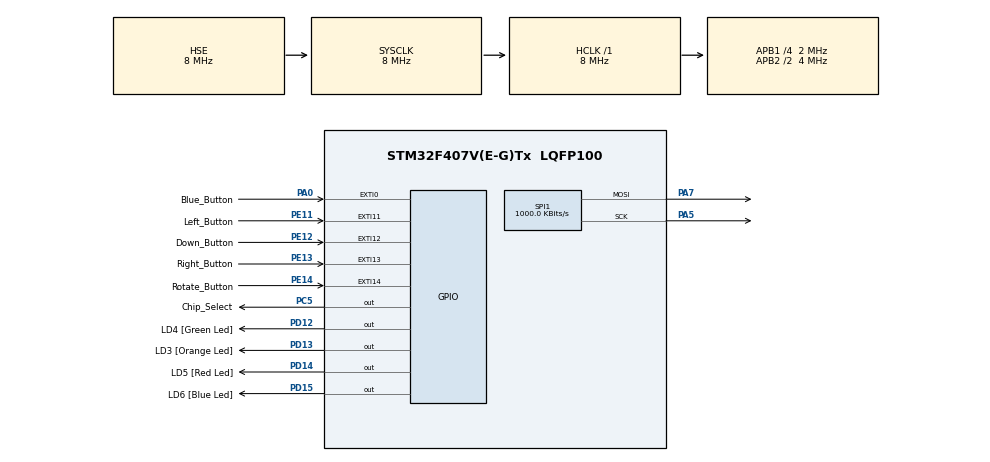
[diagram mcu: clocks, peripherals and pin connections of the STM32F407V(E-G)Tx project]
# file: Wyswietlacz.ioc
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Mcu.Family=STM32F4
Mcu.Name=STM32F407V(E-G)Tx
Mcu.Package=LQFP100
NVIC.EXTI0_IRQn=true\:0\:0\:false\:false\:true\:true
NVIC.EXTI15_10_IRQn=true\:0\:0\:false\:false\:true\:true
NVIC.PriorityGroup=NVIC_PRIORITYGROUP_0
NVIC.TIM1_UP_TIM10_IRQn=true\:0\:0\:false\:false\:true\:true
PA0-WKUP.GPIO_Label=Blue_Button
PA0-WKUP.Signal=GPXTI0
PA5.Mode=TX_Only_Simplex_Unidirect_Master
PA5.Signal=SPI1_SCK
PA7.Mode=TX_Only_Simplex_Unidirect_Master
PA7.Signal=SPI1_MOSI
PC5.GPIO_Label=Chip_Select
PC5.Signal=GPIO_Output
PD12.GPIO_Label=LD4 [Green Led]
PD12.GPIO_PuPd=GPIO_NOPULL
PD12.GPIO_Speed=GPIO_SPEED_FREQ_LOW
PD12.Signal=GPIO_Output
PD13.GPIO_Label=LD3 [Orange Led]
PD13.GPIO_PuPd=GPIO_NOPULL
PD13.GPIO_Speed=GPIO_SPEED_FREQ_LOW
PD13.Signal=GPIO_Output
PD14.GPIO_Label=LD5 [Red Led]
PD14.GPIO_PuPd=GPIO_NOPULL
PD14.GPIO_Speed=GPIO_SPEED_FREQ_LOW
PD14.Signal=GPIO_Output
PD15.GPIO_Label=LD6 [Blue Led]
PD15.GPIO_PuPd=GPIO_NOPULL
PD15.GPIO_Speed=GPIO_SPEED_FREQ_LOW
PD15.Signal=GPIO_Output
PE11.GPIO_Label=Left_Button
PE11.GPIO_ModeDefaultEXTI=GPIO_MODE_IT_FALLING
PE11.GPIO_PuPd=GPIO_PULLUP
PE11.Signal=GPXTI11
PE12.GPIO_Label=Down_Button
PE12.GPIO_ModeDefaultEXTI=GPIO_MODE_IT_FALLING
PE12.GPIO_PuPd=GPIO_PULLUP
PE12.Signal=GPXTI12
PE13.GPIO_Label=Right_Button
PE13.GPIO_ModeDefaultEXTI=GPIO_MODE_IT_FALLING
PE13.GPIO_PuPd=GPIO_PULLUP
PE13.Signal=GPXTI13
PE14.GPIO_Label=Rotate_Button
PE14.GPIO_ModeDefaultEXTI=GPIO_MODE_IT_FALLING
PE14.GPIO_PuPd=GPIO_PULLUP
PE14.Signal=GPXTI14
PH0-OSC_IN.Mode=HSE-External-Oscillator
PH0-OSC_IN.Signal=RCC_OSC_IN
PH1-OSC_OUT.Mode=HSE-External-Oscillator
PH1-OSC_OUT.Signal=RCC_OSC_OUT
ProjectManager.HeapSize=0x200
ProjectManager.StackSize=0x400
ProjectManager.TargetToolchain=SW4STM32
RCC.48MHZClocksFreq_Value=28571428.57142857
RCC.AHBFreq_Value=8000000
RCC.APB1CLKDivider=RCC_HCLK_DIV4
RCC.APB1Freq_Value=2000000
RCC.APB1TimFreq_Value=4000000
RCC.APB2CLKDivider=RCC_HCLK_DIV2
RCC.APB2Freq_Value=4000000
RCC.APB2TimFreq_Value=8000000
RCC.CortexFreq_Value=8000000
RCC.HCLKFreq_Value=8000000
RCC.HSE_VALUE=8000000
RCC.HSI_VALUE=16000000
RCC.LSE_VALUE=32768
RCC.PLLM=8
RCC.PLLN=100
RCC.PLLQ=7
RCC.SYSCLKFreq_VALUE=8000000
RCC.SYSCLKSource=RCC_SYSCLKSOURCE_HSE
RCC.VCOOutputFreq_Value=200000000
SPI1.BaudRatePrescaler=SPI_BAUDRATEPRESCALER_4
SPI1.CalculateBaudRate=1000.0 KBits/s
SPI1.DataSize=SPI_DATASIZE_16BIT
SPI1.Direction=SPI_DIRECTION_2LINES
SPI1.Mode=SPI_MODE_MASTER
SPI1.VirtualType=VM_MASTER
TIM10.Period=999
TIM10.Prescaler=8399
VP_RNG_VS_RNG.Mode=RNG_Activate
VP_TIM10_VS_ClockSourceINT.Mode=Enable_Timer
board=STM32F4DISCOVERY

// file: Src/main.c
/**
  ******************************************************************************
  * @file           : main.c
  * @brief          : Main program body
  ******************************************************************************
  ** This notice applies to any and all portions of this file
  * that are not between comment pairs USER CODE BEGIN and
  * USER CODE END. Other portions of this file, whether
  * inserted by the user or by software development tools
  * are owned by their respective copyright owners.
  *
  * COPYRIGHT(c) 2018 STMicroelectronics
  *
  * Redistribution and use in source and binary forms, with or without modification,
  * are permitted provided that the following conditions are met:
  *   1. Redistributions of source code must retain the above copyright notice,
  *      this list of conditions and the following disclaimer.
  *   2. Redistributions in binary form must reproduce the above copyright notice,
  *      this list of conditions and the following disclaimer in the documentation
  *      and/or other materials provided with the distribution.
  *   3. Neither the name of STMicroelectronics nor the names of its contributors
  *      may be used to endorse or promote products derived from this software
  *      without specific prior written permission.
  *
  * THIS SOFTWARE IS PROVIDED BY THE COPYRIGHT HOLDERS AND CONTRIBUTORS "AS IS"
  * AND ANY EXPRESS OR IMPLIED WARRANTIES, INCLUDING, BUT NOT LIMITED TO, THE
  * IMPLIED WARRANTIES OF MERCHANTABILITY AND FITNESS FOR A PARTICULAR PURPOSE ARE
  * DISCLAIMED. IN NO EVENT SHALL THE COPYRIGHT HOLDER OR CONTRIBUTORS BE LIABLE
  * FOR ANY DIRECT, INDIRECT, INCIDENTAL, SPECIAL, EXEMPLARY, OR CONSEQUENTIAL
  * DAMAGES (INCLUDING, BUT NOT LIMITED TO, PROCUREMENT OF SUBSTITUTE GOODS OR
  * SERVICES; LOSS OF USE, DATA, OR PROFITS; OR BUSINESS INTERRUPTION) HOWEVER
  * CAUSED AND ON ANY THEORY OF LIABILITY, WHETHER IN CONTRACT, STRICT LIABILITY,
  * OR TORT (INCLUDING NEGLIGENCE OR OTHERWISE) ARISING IN ANY WAY OUT OF THE USE
  * OF THIS SOFTWARE, EVEN IF ADVISED OF THE POSSIBILITY OF SUCH DAMAGE.
  *
  ******************************************************************************
  */
#include "main.h"
#include "stm32f4xx_hal.h"

/* USER CODE BEGIN Includes */
extern void GameLoop();
/* USER CODE END Includes */

RNG_HandleTypeDef hrng;

SPI_HandleTypeDef hspi1;

TIM_HandleTypeDef htim10;

/* USER CODE BEGIN PV */
/* Private variables ---------------------------------------------------------*/
/* USER CODE END PV */

void SystemClock_Config(void);
static void MX_GPIO_Init(void);
static void MX_SPI1_Init(void);
static void MX_RNG_Init(void);
static void MX_TIM10_Init(void);

/* USER CODE BEGIN PFP */
/* Private function prototypes -----------------------------------------------*/

/* USER CODE END PFP */

int main(void)
{

  /* MCU Configuration----------------------------------------------------------*/

  /* Reset of all peripherals, Initializes the Flash interface and the Systick. */
  HAL_Init();

  /* Configure the system clock */
  SystemClock_Config();

  /* Initialize all configured peripherals */
  MX_GPIO_Init();
  MX_SPI1_Init();
  MX_RNG_Init();
  MX_TIM10_Init();
  /* USER CODE BEGIN 2 */
  HAL_TIM_Base_Start_IT(&htim10);
  //RUN GAME !
  GameLoop();
  /* USER CODE END 2 */

  /* Infinite loop */
  while (1)
  {

  }

}

void SystemClock_Config(void)
{

  RCC_OscInitTypeDef RCC_OscInitStruct;
  RCC_ClkInitTypeDef RCC_ClkInitStruct;

    /**Configure the main internal regulator output voltage
    */
  __HAL_RCC_PWR_CLK_ENABLE();

  __HAL_PWR_VOLTAGESCALING_CONFIG(PWR_REGULATOR_VOLTAGE_SCALE1);

    /**Initializes the CPU, AHB and APB busses clocks
    */
  RCC_OscInitStruct.OscillatorType = RCC_OSCILLATORTYPE_HSI|RCC_OSCILLATORTYPE_HSE;
  RCC_OscInitStruct.HSEState = RCC_HSE_ON;
  RCC_OscInitStruct.HSIState = RCC_HSI_ON;
  RCC_OscInitStruct.HSICalibrationValue = 16;
  RCC_OscInitStruct.PLL.PLLState = RCC_PLL_ON;
  RCC_OscInitStruct.PLL.PLLSource = RCC_PLLSOURCE_HSI;
  RCC_OscInitStruct.PLL.PLLM = 8;
  RCC_OscInitStruct.PLL.PLLN = 100;
  RCC_OscInitStruct.PLL.PLLP = RCC_PLLP_DIV2;
  RCC_OscInitStruct.PLL.PLLQ = 7;
  if (HAL_RCC_OscConfig(&RCC_OscInitStruct) != HAL_OK)
  {
    _Error_Handler(__FILE__, __LINE__);
  }

    /**Initializes the CPU, AHB and APB busses clocks
    */
  RCC_ClkInitStruct.ClockType = RCC_CLOCKTYPE_HCLK|RCC_CLOCKTYPE_SYSCLK
                              |RCC_CLOCKTYPE_PCLK1|RCC_CLOCKTYPE_PCLK2;
  RCC_ClkInitStruct.SYSCLKSource = RCC_SYSCLKSOURCE_HSE;
  RCC_ClkInitStruct.AHBCLKDivider = RCC_SYSCLK_DIV1;
  RCC_ClkInitStruct.APB1CLKDivider = RCC_HCLK_DIV4;
  RCC_ClkInitStruct.APB2CLKDivider = RCC_HCLK_DIV2;

  if (HAL_RCC_ClockConfig(&RCC_ClkInitStruct, FLASH_LATENCY_0) != HAL_OK)
  {
    _Error_Handler(__FILE__, __LINE__);
  }

    /**Configure the Systick interrupt time
    */
  HAL_SYSTICK_Config(HAL_RCC_GetHCLKFreq()/1000);

    /**Configure the Systick
    */
  HAL_SYSTICK_CLKSourceConfig(SYSTICK_CLKSOURCE_HCLK);

  /* SysTick_IRQn interrupt configuration */
  HAL_NVIC_SetPriority(SysTick_IRQn, 0, 0);
}

/* RNG init function */
static void MX_RNG_Init(void)
{

  hrng.Instance = RNG;
  if (HAL_RNG_Init(&hrng) != HAL_OK)
  {
    _Error_Handler(__FILE__, __LINE__);
  }

}

/* SPI1 init function */
static void MX_SPI1_Init(void)
{

  /* SPI1 parameter configuration*/
  hspi1.Instance = SPI1;
  hspi1.Init.Mode = SPI_MODE_MASTER;
  hspi1.Init.Direction = SPI_DIRECTION_2LINES;
  hspi1.Init.DataSize = SPI_DATASIZE_16BIT;
  hspi1.Init.CLKPolarity = SPI_POLARITY_LOW;
  hspi1.Init.CLKPhase = SPI_PHASE_1EDGE;
  hspi1.Init.NSS = SPI_NSS_SOFT;
  hspi1.Init.BaudRatePrescaler = SPI_BAUDRATEPRESCALER_4;
  hspi1.Init.FirstBit = SPI_FIRSTBIT_MSB;
  hspi1.Init.TIMode = SPI_TIMODE_DISABLE;
  hspi1.Init.CRCCalculation = SPI_CRCCALCULATION_DISABLE;
  hspi1.Init.CRCPolynomial = 10;
  if (HAL_SPI_Init(&hspi1) != HAL_OK)
  {
    _Error_Handler(__FILE__, __LINE__);
  }

}

/* TIM10 init function */
static void MX_TIM10_Init(void)
{

  htim10.Instance = TIM10;
  htim10.Init.Prescaler = 8399;
  htim10.Init.CounterMode = TIM_COUNTERMODE_UP;
  htim10.Init.Period = 999;
  htim10.Init.ClockDivision = TIM_CLOCKDIVISION_DIV1;
  if (HAL_TIM_Base_Init(&htim10) != HAL_OK)
  {
    _Error_Handler(__FILE__, __LINE__);
  }

}

/** Configure pins as
        * Analog
        * Input
        * Output
        * EVENT_OUT
        * EXTI
*/
static void MX_GPIO_Init(void)
{

  GPIO_InitTypeDef GPIO_InitStruct;

  /* GPIO Ports Clock Enable */
  __HAL_RCC_GPIOH_CLK_ENABLE();
  __HAL_RCC_GPIOA_CLK_ENABLE();
  __HAL_RCC_GPIOC_CLK_ENABLE();
  __HAL_RCC_GPIOE_CLK_ENABLE();
  __HAL_RCC_GPIOD_CLK_ENABLE();

  /*Configure GPIO pin Output Level */
  HAL_GPIO_WritePin(Chip_Select_GPIO_Port, Chip_Select_Pin, GPIO_PIN_RESET);

  /*Configure GPIO pin Output Level */
  HAL_GPIO_WritePin(GPIOD, LD4_Pin|LD3_Pin|LD5_Pin|LD6_Pin, GPIO_PIN_RESET);

  /*Configure GPIO pin : Blue_Button_Pin */
  GPIO_InitStruct.Pin = Blue_Button_Pin;
  GPIO_InitStruct.Mode = GPIO_MODE_IT_RISING;
  GPIO_InitStruct.Pull = GPIO_NOPULL;
  HAL_GPIO_Init(Blue_Button_GPIO_Port, &GPIO_InitStruct);

  /*Configure GPIO pin : Chip_Select_Pin */
  GPIO_InitStruct.Pin = Chip_Select_Pin;
  GPIO_InitStruct.Mode = GPIO_MODE_OUTPUT_PP;
  GPIO_InitStruct.Pull = GPIO_NOPULL;
  GPIO_InitStruct.Speed = GPIO_SPEED_FREQ_LOW;
  HAL_GPIO_Init(Chip_Select_GPIO_Port, &GPIO_InitStruct);

  /*Configure GPIO pins : Left_Button_Pin Down_Button_Pin Right_Button_Pin Rotate_Button_Pin */
  GPIO_InitStruct.Pin = Left_Button_Pin|Down_Button_Pin|Right_Button_Pin|Rotate_Button_Pin;
  GPIO_InitStruct.Mode = GPIO_MODE_IT_FALLING;
  GPIO_InitStruct.Pull = GPIO_PULLUP;
  HAL_GPIO_Init(GPIOE, &GPIO_InitStruct);

  /*Configure GPIO pins : LD4_Pin LD3_Pin LD5_Pin LD6_Pin */
  GPIO_InitStruct.Pin = LD4_Pin|LD3_Pin|LD5_Pin|LD6_Pin;
  GPIO_InitStruct.Mode = GPIO_MODE_OUTPUT_PP;
  GPIO_InitStruct.Pull = GPIO_NOPULL;
  GPIO_InitStruct.Speed = GPIO_SPEED_FREQ_LOW;
  HAL_GPIO_Init(GPIOD, &GPIO_InitStruct);

  /* EXTI interrupt init*/
  HAL_NVIC_SetPriority(EXTI0_IRQn, 0, 0);
  HAL_NVIC_EnableIRQ(EXTI0_IRQn);

  HAL_NVIC_SetPriority(EXTI15_10_IRQn, 0, 0);
  HAL_NVIC_EnableIRQ(EXTI15_10_IRQn);

}

void _Error_Handler(char *file, int line)
{
  while(1)
  {
  }
}

/************************ (C) COPYRIGHT STMicroelectronics *****END OF FILE****/
